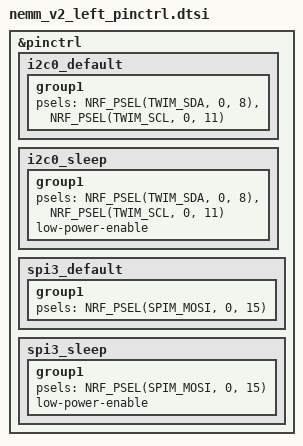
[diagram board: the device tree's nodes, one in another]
/*
# Copyright (c) 2021 The ZMK Contributors
*
* SPDX-License-Identifier: MIT
*/

#include <dt-bindings/led/led.h>

&pinctrl {
	i2c0_default: i2c0_default {
        group1 {
            psels = <NRF_PSEL(TWIM_SDA, 0, 8)>,
                    <NRF_PSEL(TWIM_SCL, 0, 11)>;
        };
    };

    i2c0_sleep: i2c0_sleep {
        group1 {
            psels = <NRF_PSEL(TWIM_SDA, 0, 8)>,
                    <NRF_PSEL(TWIM_SCL, 0, 11)>;
            low-power-enable;
        };
    };

	spi3_default: spi3_default {
        group1 {
            psels = <NRF_PSEL(SPIM_MOSI, 0, 15)>;
        };
    };

    spi3_sleep: spi3_sleep {
        group1 {
            psels = <NRF_PSEL(SPIM_MOSI, 0, 15)>;
            low-power-enable;
        };
    };
};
